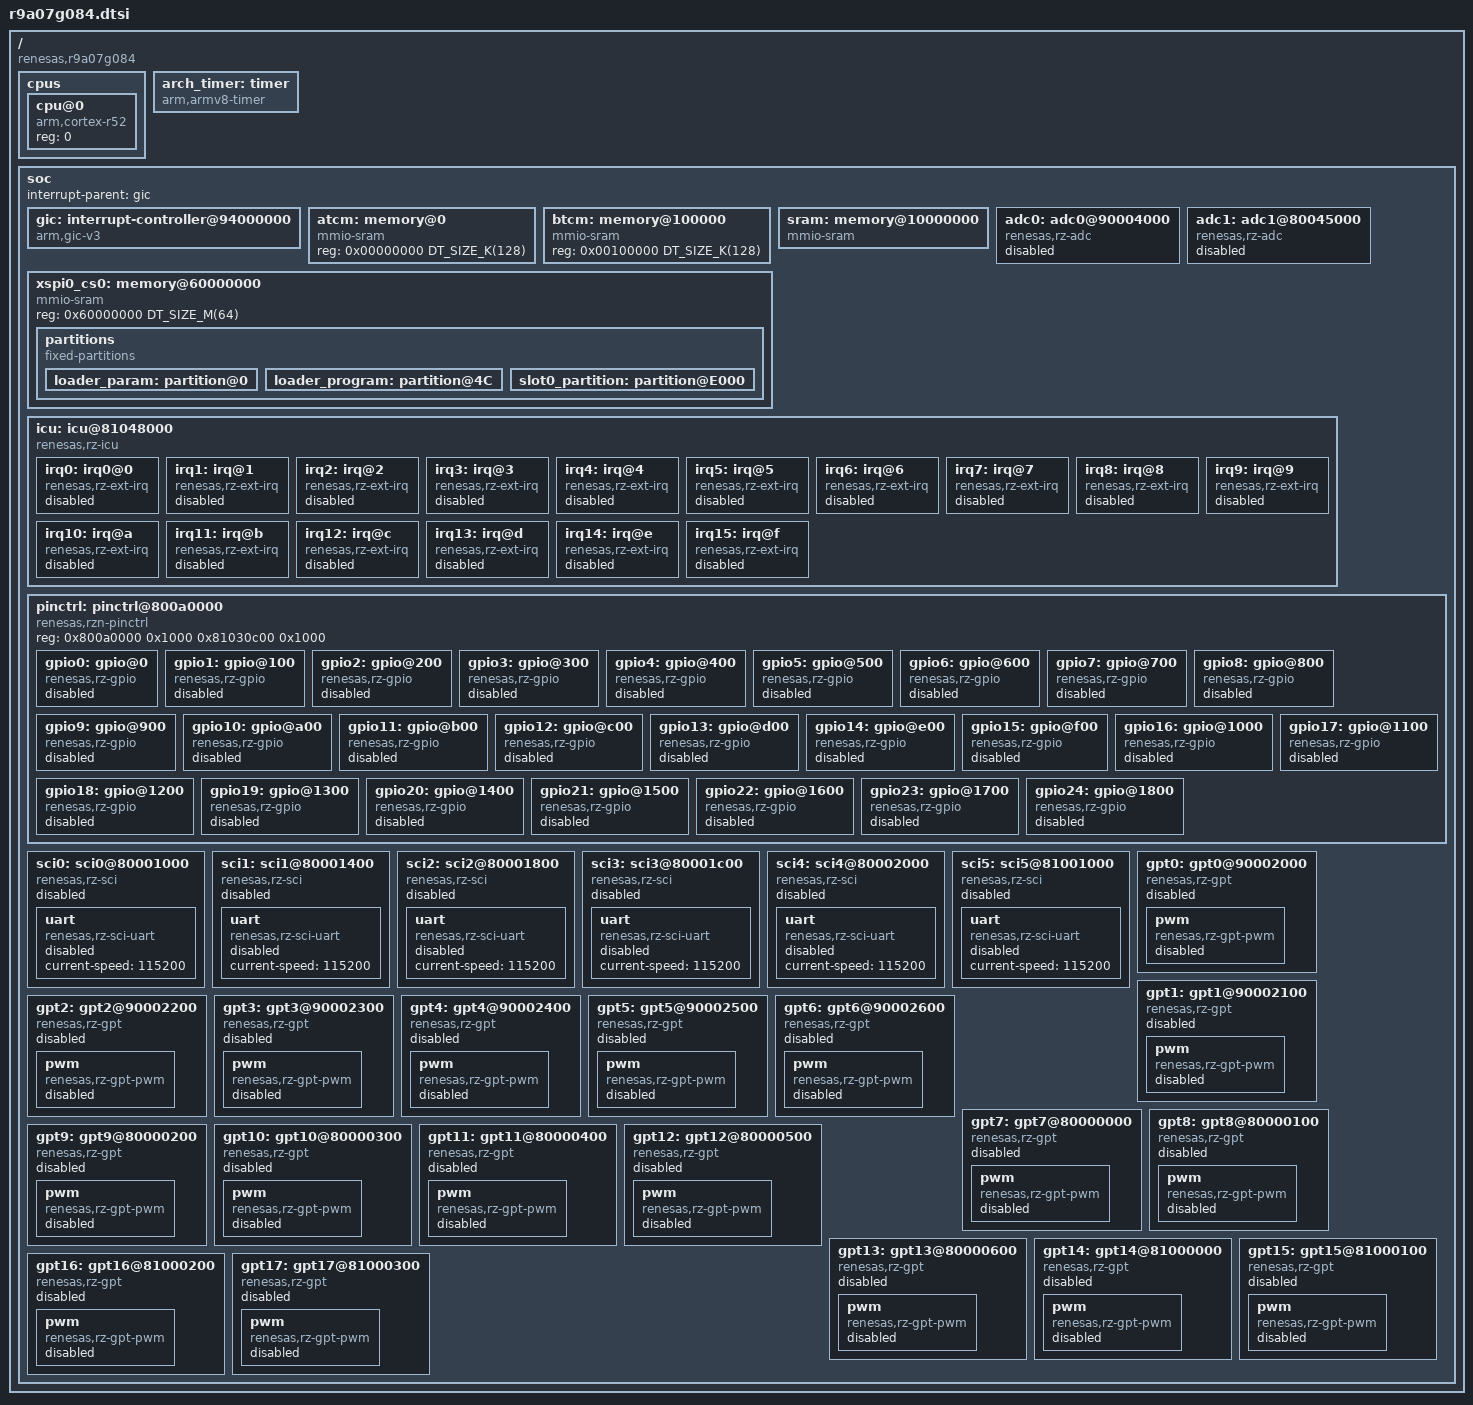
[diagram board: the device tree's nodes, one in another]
/*
 * Copyright (c) 2025 Renesas Electronics Corporation
 * SPDX-License-Identifier: Apache-2.0
 */

#include <mem.h>
#include <arm/armv8-r.dtsi>
#include <zephyr/dt-bindings/interrupt-controller/arm-gic.h>
#include <zephyr/dt-bindings/adc/adc.h>

/ {
	#address-cells = <1>;
	#size-cells = <1>;
	compatible = "renesas,r9a07g084";

	cpus {
		#address-cells = <1>;
		#size-cells = <0>;

		cpu@0 {
			device_type = "cpu";
			compatible = "arm,cortex-r52";
			reg = <0>;
		};
	};

	arch_timer: timer {
		compatible = "arm,armv8-timer";
		interrupts = <GIC_PPI 13 IRQ_TYPE_LEVEL IRQ_DEFAULT_PRIORITY>,
				<GIC_PPI 14 IRQ_TYPE_LEVEL IRQ_DEFAULT_PRIORITY>,
				<GIC_PPI 11 IRQ_TYPE_LEVEL IRQ_DEFAULT_PRIORITY>,
				<GIC_PPI 10 IRQ_TYPE_LEVEL IRQ_DEFAULT_PRIORITY>;
		interrupt-parent = <&gic>;
	};

	soc {
		interrupt-parent = <&gic>;

		gic: interrupt-controller@94000000 {
			compatible = "arm,gic-v3", "arm,gic";
			reg = <0x94000000 0x10000>,
				<0x94100000 0x80000>;
			interrupt-controller;
			#interrupt-cells = <4>;
			status = "okay";
		};

		atcm: memory@0 {
			compatible = "mmio-sram";
			reg = <0x00000000 DT_SIZE_K(128)>;
		};

		btcm: memory@100000 {
			compatible = "mmio-sram";
			reg = <0x00100000 DT_SIZE_K(128)>;
		};

		sram: memory@10000000 {
			compatible = "mmio-sram";
			reg = <0x10000000 (DT_SIZE_M(1) + DT_SIZE_K(512))>;
		};

		xspi0_cs0: memory@60000000 {
			compatible = "mmio-sram";
			reg = <0x60000000 DT_SIZE_M(64)>;

			partitions {
				compatible = "fixed-partitions";
				#address-cells = <1>;
				#size-cells = <1>;

				loader_param: partition@0 {
					label = "loader-param";
					reg = <0x00000000 0x4C>;
					read-only;
				};

				loader_program: partition@4C {
					label = "loader-program";
					reg = <0x0000004C (DT_SIZE_K(56) - 0x4C)>;
					read-only;
				};

				slot0_partition: partition@E000 {
					label = "image-0";
					reg = <0x0000E000 (DT_SIZE_M(64) - DT_SIZE_K(56))>;
					read-only;
				};
			};
		};

		adc0: adc0@90004000 {
			compatible = "renesas,rz-adc";
			reg = <0x90004000 0x1000>;
			unit = <0>;
			interrupts = <GIC_SPI 345 IRQ_TYPE_EDGE IRQ_DEFAULT_PRIORITY>;
			interrupt-names = "scanend";
			#io-channel-cells = <1>;
			vref-mv = <1800>;
			channel-available-mask = <0xF>;
			status = "disabled";
		};

		adc1: adc1@80045000 {
			compatible = "renesas,rz-adc";
			reg = <0x80045000 0x1000>;
			unit = <1>;
			interrupts = <GIC_SPI 350 IRQ_TYPE_EDGE IRQ_DEFAULT_PRIORITY>;
			interrupt-names = "scanend";
			#io-channel-cells = <1>;
			vref-mv = <1800>;
			channel-available-mask = <0xFF>;
			status = "disabled";
		};

		icu: icu@81048000 {
			compatible = "renesas,rz-icu";
			reg = <0x81048000 0x1000>;
			interrupt-parent = <&gic>;
			#address-cells = <1>;
			#size-cells = <0>;

			irq0: irq0@0 {
				compatible = "renesas,rz-ext-irq";
				reg = <0x0>;
				interrupts = <GIC_SPI 6 IRQ_TYPE_EDGE IRQ_DEFAULT_PRIORITY>;
				interrupt-controller;
				#interrupt-cells = <2>;
				status = "disabled";
			};

			irq1: irq@1 {
				compatible = "renesas,rz-ext-irq";
				reg = <0x1>;
				interrupts = <GIC_SPI 7 IRQ_TYPE_EDGE IRQ_DEFAULT_PRIORITY>;
				interrupt-controller;
				#interrupt-cells = <2>;
				status = "disabled";
			};

			irq2: irq@2 {
				compatible = "renesas,rz-ext-irq";
				reg = <0x2>;
				interrupts = <GIC_SPI 8 IRQ_TYPE_EDGE IRQ_DEFAULT_PRIORITY>;
				interrupt-controller;
				#interrupt-cells = <2>;
				status = "disabled";
			};

			irq3: irq@3 {
				compatible = "renesas,rz-ext-irq";
				reg = <0x3>;
				interrupts = <GIC_SPI 9 IRQ_TYPE_EDGE IRQ_DEFAULT_PRIORITY>;
				interrupt-controller;
				#interrupt-cells = <2>;
				status = "disabled";
			};

			irq4: irq@4 {
				compatible = "renesas,rz-ext-irq";
				reg = <0x4>;
				interrupts = <GIC_SPI 10 IRQ_TYPE_EDGE IRQ_DEFAULT_PRIORITY>;
				interrupt-controller;
				#interrupt-cells = <2>;
				status = "disabled";
			};

			irq5: irq@5 {
				compatible = "renesas,rz-ext-irq";
				reg = <0x5>;
				interrupts = <GIC_SPI 11 IRQ_TYPE_EDGE IRQ_DEFAULT_PRIORITY>;
				interrupt-controller;
				#interrupt-cells = <2>;
				status = "disabled";
			};

			irq6: irq@6 {
				compatible = "renesas,rz-ext-irq";
				reg = <0x6>;
				interrupts = <GIC_SPI 12 IRQ_TYPE_EDGE IRQ_DEFAULT_PRIORITY>;
				interrupt-controller;
				#interrupt-cells = <2>;
				status = "disabled";
			};

			irq7: irq@7 {
				compatible = "renesas,rz-ext-irq";
				reg = <0x7>;
				interrupts = <GIC_SPI 13 IRQ_TYPE_EDGE IRQ_DEFAULT_PRIORITY>;
				interrupt-controller;
				#interrupt-cells = <2>;
				status = "disabled";
			};

			irq8: irq@8 {
				compatible = "renesas,rz-ext-irq";
				reg = <0x8>;
				interrupts = <GIC_SPI 14 IRQ_TYPE_EDGE IRQ_DEFAULT_PRIORITY>;
				interrupt-controller;
				#interrupt-cells = <2>;
				status = "disabled";
			};

			irq9: irq@9 {
				compatible = "renesas,rz-ext-irq";
				reg = <0x9>;
				interrupts = <GIC_SPI 15 IRQ_TYPE_EDGE IRQ_DEFAULT_PRIORITY>;
				interrupt-controller;
				#interrupt-cells = <2>;
				status = "disabled";
			};

			irq10: irq@a {
				compatible = "renesas,rz-ext-irq";
				reg = <0xa>;
				interrupts = <GIC_SPI 16 IRQ_TYPE_EDGE IRQ_DEFAULT_PRIORITY>;
				interrupt-controller;
				#interrupt-cells = <2>;
				status = "disabled";
			};

			irq11: irq@b {
				compatible = "renesas,rz-ext-irq";
				reg = <0xb>;
				interrupts = <GIC_SPI 17 IRQ_TYPE_EDGE IRQ_DEFAULT_PRIORITY>;
				interrupt-controller;
				#interrupt-cells = <2>;
				status = "disabled";
			};

			irq12: irq@c {
				compatible = "renesas,rz-ext-irq";
				reg = <0xc>;
				interrupts = <GIC_SPI 18 IRQ_TYPE_EDGE IRQ_DEFAULT_PRIORITY>;
				interrupt-controller;
				#interrupt-cells = <2>;
				status = "disabled";
			};

			irq13: irq@d {
				compatible = "renesas,rz-ext-irq";
				reg = <0xd>;
				interrupts = <GIC_SPI 19 IRQ_TYPE_EDGE IRQ_DEFAULT_PRIORITY>;
				interrupt-controller;
				#interrupt-cells = <2>;
				status = "disabled";
			};

			irq14: irq@e {
				compatible = "renesas,rz-ext-irq";
				reg = <0xe>;
				interrupts = <GIC_SPI 394 IRQ_TYPE_EDGE IRQ_DEFAULT_PRIORITY>;
				interrupt-controller;
				#interrupt-cells = <2>;
				status = "disabled";
			};

			irq15: irq@f {
				compatible = "renesas,rz-ext-irq";
				reg = <0xf>;
				interrupts = <GIC_SPI 395 IRQ_TYPE_EDGE IRQ_DEFAULT_PRIORITY>;
				interrupt-controller;
				#interrupt-cells = <2>;
				status = "disabled";
			};
		};

		pinctrl: pinctrl@800a0000 {
			compatible = "renesas,rzn-pinctrl";
			reg = <0x800a0000 0x1000 0x81030c00 0x1000>;
			#address-cells = <1>;
			#size-cells = <0>;

			gpio0: gpio@0 {
				compatible = "renesas,rz-gpio";
				gpio-controller;
				#gpio-cells = <2>;
				ngpios = <8>;
				reg = <0x0>;
				status = "disabled";
			};

			gpio1: gpio@100 {
				compatible = "renesas,rz-gpio";
				gpio-controller;
				#gpio-cells= <2>;
				ngpios = <8>;
				reg = <0x0100>;
				status = "disabled";
			};

			gpio2: gpio@200 {
				compatible = "renesas,rz-gpio";
				gpio-controller;
				#gpio-cells= <2>;
				ngpios = <8>;
				reg = <0x0200>;
				status = "disabled";
			};

			gpio3: gpio@300 {
				compatible = "renesas,rz-gpio";
				gpio-controller;
				#gpio-cells= <2>;
				ngpios = <8>;
				gpio-reserved-ranges = <1 4>;
				reg = <0x0300>;
				status = "disabled";
			};

			gpio4: gpio@400 {
				compatible = "renesas,rz-gpio";
				gpio-controller;
				#gpio-cells= <2>;
				ngpios = <8>;
				gpio-reserved-ranges = <2 2>;
				reg = <0x0400>;
				status = "disabled";
			};

			gpio5: gpio@500 {
				compatible = "renesas,rz-gpio";
				gpio-controller;
				#gpio-cells= <2>;
				ngpios = <8>;
				reg = <0x0500>;
				status = "disabled";
			};

			gpio6: gpio@600 {
				compatible = "renesas,rz-gpio";
				gpio-controller;
				#gpio-cells= <2>;
				ngpios = <8>;
				reg = <0x0600>;
				status = "disabled";
			};

			gpio7: gpio@700 {
				compatible = "renesas,rz-gpio";
				gpio-controller;
				#gpio-cells= <2>;
				ngpios = <5>;
				reg = <0x0700>;
				status = "disabled";
			};

			gpio8: gpio@800 {
				compatible = "renesas,rz-gpio";
				gpio-controller;
				#gpio-cells= <2>;
				ngpios = <8>;
				gpio-reserved-ranges = <0 4>;
				reg = <0x0800>;
				status = "disabled";
			};

			gpio9: gpio@900 {
				compatible = "renesas,rz-gpio";
				gpio-controller;
				#gpio-cells= <2>;
				ngpios = <8>;
				reg = <0x0900>;
				status = "disabled";
			};

			gpio10: gpio@a00 {
				compatible = "renesas,rz-gpio";
				gpio-controller;
				#gpio-cells= <2>;
				ngpios = <5>;
				reg = <0x0a00>;
				status = "disabled";
			};

			gpio11: gpio@b00 {
				compatible = "renesas,rz-gpio";
				gpio-controller;
				#gpio-cells= <2>;
				ngpios = <0>;
				reg = <0x0b00>;
				status = "disabled";
			};

			gpio12: gpio@c00 {
				compatible = "renesas,rz-gpio";
				gpio-controller;
				#gpio-cells= <2>;
				ngpios = <5>;
				gpio-reserved-ranges = <0 4>;
				reg = <0x0c00>;
				status = "disabled";
			};

			gpio13: gpio@d00 {
				compatible = "renesas,rz-gpio";
				gpio-controller;
				#gpio-cells= <2>;
				ngpios = <8>;
				gpio-reserved-ranges = <0 2>;
				reg = <0x0d00>;
				status = "disabled";
			};

			gpio14: gpio@e00 {
				compatible = "renesas,rz-gpio";
				gpio-controller;
				#gpio-cells= <2>;
				ngpios = <8>;
				reg = <0x0e00>;
				status = "disabled";
			};

			gpio15: gpio@f00 {
				compatible = "renesas,rz-gpio";
				gpio-controller;
				#gpio-cells= <2>;
				ngpios = <8>;
				reg = <0x0f00>;
				status = "disabled";
			};

			gpio16: gpio@1000 {
				compatible = "renesas,rz-gpio";
				gpio-controller;
				#gpio-cells= <2>;
				ngpios = <8>;
				gpio-reserved-ranges = <4 1>;
				reg = <0x1000>;
				status = "disabled";
			};

			gpio17: gpio@1100 {
				compatible = "renesas,rz-gpio";
				gpio-controller;
				#gpio-cells= <2>;
				ngpios = <8>;
				gpio-reserved-ranges = <1 2>;
				reg = <0x1100>;
				status = "disabled";
			};

			gpio18: gpio@1200 {
				compatible = "renesas,rz-gpio";
				gpio-controller;
				#gpio-cells= <2>;
				ngpios = <7>;
				reg = <0x1200>;
				status = "disabled";
			};

			gpio19: gpio@1300 {
				compatible = "renesas,rz-gpio";
				gpio-controller;
				#gpio-cells= <2>;
				ngpios = <1>;
				reg = <0x1300>;
				status = "disabled";
			};

			gpio20: gpio@1400 {
				compatible = "renesas,rz-gpio";
				gpio-controller;
				#gpio-cells= <2>;
				ngpios = <5>;
				gpio-reserved-ranges = <0 1>;
				reg = <0x1400>;
				status = "disabled";
			};

			gpio21: gpio@1500 {
				compatible = "renesas,rz-gpio";
				gpio-controller;
				#gpio-cells= <2>;
				ngpios = <8>;
				gpio-reserved-ranges = <0 1>;
				reg = <0x1500>;
				status = "disabled";
			};

			gpio22: gpio@1600 {
				compatible = "renesas,rz-gpio";
				gpio-controller;
				#gpio-cells= <2>;
				ngpios = <4>;
				reg = <0x1600>;
				status = "disabled";
			};

			gpio23: gpio@1700 {
				compatible = "renesas,rz-gpio";
				gpio-controller;
				#gpio-cells= <2>;
				ngpios = <8>;
				gpio-reserved-ranges = <0 7>;
				reg = <0x1700>;
				status = "disabled";
			};

			gpio24: gpio@1800 {
				compatible = "renesas,rz-gpio";
				gpio-controller;
				#gpio-cells= <2>;
				ngpios = <3>;
				reg = <0x1800>;
				status = "disabled";
			};
		};

		sci0: sci0@80001000 {
			compatible = "renesas,rz-sci";
			reg = <0x80001000 0x400>;
			channel = <0>;
			interrupts = <GIC_SPI 288 IRQ_TYPE_LEVEL IRQ_DEFAULT_PRIORITY>,
					<GIC_SPI 289 IRQ_TYPE_EDGE IRQ_DEFAULT_PRIORITY>,
					<GIC_SPI 290 IRQ_TYPE_EDGE IRQ_DEFAULT_PRIORITY>,
					<GIC_SPI 291 IRQ_TYPE_LEVEL IRQ_DEFAULT_PRIORITY>;
			interrupt-names = "eri", "rxi", "txi", "tei";
			status = "disabled";

			uart {
				compatible = "renesas,rz-sci-uart";
				current-speed = <115200>;
				status = "disabled";
			};
		};

		sci1: sci1@80001400 {
			compatible = "renesas,rz-sci";
			reg = <0x80001400 0x400>;
			channel = <1>;
			interrupts = <GIC_SPI 292 IRQ_TYPE_LEVEL IRQ_DEFAULT_PRIORITY>,
					<GIC_SPI 293 IRQ_TYPE_EDGE IRQ_DEFAULT_PRIORITY>,
					<GIC_SPI 294 IRQ_TYPE_EDGE IRQ_DEFAULT_PRIORITY>,
					<GIC_SPI 295 IRQ_TYPE_LEVEL IRQ_DEFAULT_PRIORITY>;
			interrupt-names = "eri", "rxi", "txi", "tei";
			status = "disabled";

			uart {
				compatible = "renesas,rz-sci-uart";
				current-speed = <115200>;
				status = "disabled";
			};
		};

		sci2: sci2@80001800 {
			compatible = "renesas,rz-sci";
			reg = <0x80001800 0x400>;
			channel = <2>;
			interrupts = <GIC_SPI 296 IRQ_TYPE_LEVEL IRQ_DEFAULT_PRIORITY>,
					<GIC_SPI 297 IRQ_TYPE_EDGE IRQ_DEFAULT_PRIORITY>,
					<GIC_SPI 298 IRQ_TYPE_EDGE IRQ_DEFAULT_PRIORITY>,
					<GIC_SPI 299 IRQ_TYPE_LEVEL IRQ_DEFAULT_PRIORITY>;
			interrupt-names = "eri", "rxi", "txi", "tei";
			status = "disabled";

			uart {
				compatible = "renesas,rz-sci-uart";
				current-speed = <115200>;
				status = "disabled";
			};
		};

		sci3: sci3@80001c00 {
			compatible = "renesas,rz-sci";
			reg = <0x80001c00 0x400>;
			channel = <3>;
			interrupts = <GIC_SPI 300 IRQ_TYPE_LEVEL IRQ_DEFAULT_PRIORITY>,
					<GIC_SPI 301 IRQ_TYPE_EDGE IRQ_DEFAULT_PRIORITY>,
					<GIC_SPI 302 IRQ_TYPE_EDGE IRQ_DEFAULT_PRIORITY>,
					<GIC_SPI 303 IRQ_TYPE_LEVEL IRQ_DEFAULT_PRIORITY>;
			interrupt-names = "eri", "rxi", "txi", "tei";
			status = "disabled";

			uart {
				compatible = "renesas,rz-sci-uart";
				current-speed = <115200>;
				status = "disabled";
			};
		};

		sci4: sci4@80002000 {
			compatible = "renesas,rz-sci";
			reg = <0x80002000 0x400>;
			channel = <4>;
			interrupts = <GIC_SPI 304 IRQ_TYPE_LEVEL IRQ_DEFAULT_PRIORITY>,
					<GIC_SPI 305 IRQ_TYPE_EDGE IRQ_DEFAULT_PRIORITY>,
					<GIC_SPI 306 IRQ_TYPE_EDGE IRQ_DEFAULT_PRIORITY>,
					<GIC_SPI 307 IRQ_TYPE_LEVEL IRQ_DEFAULT_PRIORITY>;
			interrupt-names = "eri", "rxi", "txi", "tei";
			status = "disabled";

			uart {
				compatible = "renesas,rz-sci-uart";
				current-speed = <115200>;
				status = "disabled";
			};
		};

		sci5: sci5@81001000 {
			compatible = "renesas,rz-sci";
			reg = <0x81001000 0x400>;
			channel = <5>;
			interrupts = <GIC_SPI 435 IRQ_TYPE_LEVEL IRQ_DEFAULT_PRIORITY>,
					<GIC_SPI 436 IRQ_TYPE_EDGE IRQ_DEFAULT_PRIORITY>,
					<GIC_SPI 437 IRQ_TYPE_EDGE IRQ_DEFAULT_PRIORITY>,
					<GIC_SPI 438 IRQ_TYPE_LEVEL IRQ_DEFAULT_PRIORITY>;
			interrupt-names = "eri", "rxi", "txi", "tei";
			status = "disabled";

			uart {
				compatible = "renesas,rz-sci-uart";
				current-speed = <115200>;
				status = "disabled";
			};
		};

		gpt0: gpt0@90002000 {
			compatible = "renesas,rz-gpt";
			reg = <0x90002000 0x100>;
			channel = <0>;
			interrupts = <GIC_SPI 116 IRQ_TYPE_EDGE IRQ_DEFAULT_PRIORITY>,
					<GIC_SPI 117 IRQ_TYPE_EDGE IRQ_DEFAULT_PRIORITY>,
					<GIC_SPI 118 IRQ_TYPE_EDGE IRQ_DEFAULT_PRIORITY>,
					<GIC_SPI 119 IRQ_TYPE_EDGE IRQ_DEFAULT_PRIORITY>,
					<GIC_SPI 120 IRQ_TYPE_EDGE IRQ_DEFAULT_PRIORITY>,
					<GIC_SPI 121 IRQ_TYPE_EDGE IRQ_DEFAULT_PRIORITY>,
					<GIC_SPI 122 IRQ_TYPE_EDGE IRQ_DEFAULT_PRIORITY>,
					<GIC_SPI 123 IRQ_TYPE_EDGE IRQ_DEFAULT_PRIORITY>,
					<GIC_SPI 124 IRQ_TYPE_EDGE IRQ_DEFAULT_PRIORITY>;
			interrupt-names = "ccmpa", "ccmpb", "cmpc", "cmpd", "cmpe",
					  "cmpf", "ovf", "udf", "dte";
			prescaler = <1>;
			status = "disabled";

			pwm {
				compatible = "renesas,rz-gpt-pwm";
				#pwm-cells = <3>;
				status = "disabled";
			};
		};

		gpt1: gpt1@90002100 {
			compatible = "renesas,rz-gpt";
			reg = <0x90002100 0x100>;
			channel = <1>;
			interrupts = <GIC_SPI 125 IRQ_TYPE_EDGE IRQ_DEFAULT_PRIORITY>,
					<GIC_SPI 126 IRQ_TYPE_EDGE IRQ_DEFAULT_PRIORITY>,
					<GIC_SPI 127 IRQ_TYPE_EDGE IRQ_DEFAULT_PRIORITY>,
					<GIC_SPI 128 IRQ_TYPE_EDGE IRQ_DEFAULT_PRIORITY>,
					<GIC_SPI 129 IRQ_TYPE_EDGE IRQ_DEFAULT_PRIORITY>,
					<GIC_SPI 130 IRQ_TYPE_EDGE IRQ_DEFAULT_PRIORITY>,
					<GIC_SPI 131 IRQ_TYPE_EDGE IRQ_DEFAULT_PRIORITY>,
					<GIC_SPI 132 IRQ_TYPE_EDGE IRQ_DEFAULT_PRIORITY>,
					<GIC_SPI 133 IRQ_TYPE_EDGE IRQ_DEFAULT_PRIORITY>;
			interrupt-names = "ccmpa", "ccmpb", "cmpc", "cmpd", "cmpe",
					  "cmpf", "ovf", "udf", "dte";
			prescaler = <1>;
			status = "disabled";

			pwm {
				compatible = "renesas,rz-gpt-pwm";
				#pwm-cells = <3>;
				status = "disabled";
			};
		};

		gpt2: gpt2@90002200 {
			compatible = "renesas,rz-gpt";
			reg = <0x90002200 0x100>;
			channel = <2>;
			interrupts = <GIC_SPI 134 IRQ_TYPE_EDGE IRQ_DEFAULT_PRIORITY>,
					<GIC_SPI 135 IRQ_TYPE_EDGE IRQ_DEFAULT_PRIORITY>,
					<GIC_SPI 136 IRQ_TYPE_EDGE IRQ_DEFAULT_PRIORITY>,
					<GIC_SPI 137 IRQ_TYPE_EDGE IRQ_DEFAULT_PRIORITY>,
					<GIC_SPI 138 IRQ_TYPE_EDGE IRQ_DEFAULT_PRIORITY>,
					<GIC_SPI 139 IRQ_TYPE_EDGE IRQ_DEFAULT_PRIORITY>,
					<GIC_SPI 140 IRQ_TYPE_EDGE IRQ_DEFAULT_PRIORITY>,
					<GIC_SPI 141 IRQ_TYPE_EDGE IRQ_DEFAULT_PRIORITY>,
					<GIC_SPI 142 IRQ_TYPE_EDGE IRQ_DEFAULT_PRIORITY>;
			interrupt-names = "ccmpa", "ccmpb", "cmpc", "cmpd", "cmpe",
					  "cmpf", "ovf", "udf", "dte";
			prescaler = <1>;
			status = "disabled";

			pwm {
				compatible = "renesas,rz-gpt-pwm";
				#pwm-cells = <3>;
				status = "disabled";
			};
		};

		gpt3: gpt3@90002300 {
			compatible = "renesas,rz-gpt";
			reg = <0x90002300 0x100>;
			channel = <3>;
			interrupts = <GIC_SPI 143 IRQ_TYPE_EDGE IRQ_DEFAULT_PRIORITY>,
					<GIC_SPI 144 IRQ_TYPE_EDGE IRQ_DEFAULT_PRIORITY>,
					<GIC_SPI 145 IRQ_TYPE_EDGE IRQ_DEFAULT_PRIORITY>,
					<GIC_SPI 146 IRQ_TYPE_EDGE IRQ_DEFAULT_PRIORITY>,
					<GIC_SPI 147 IRQ_TYPE_EDGE IRQ_DEFAULT_PRIORITY>,
					<GIC_SPI 148 IRQ_TYPE_EDGE IRQ_DEFAULT_PRIORITY>,
					<GIC_SPI 149 IRQ_TYPE_EDGE IRQ_DEFAULT_PRIORITY>,
					<GIC_SPI 150 IRQ_TYPE_EDGE IRQ_DEFAULT_PRIORITY>,
					<GIC_SPI 151 IRQ_TYPE_EDGE IRQ_DEFAULT_PRIORITY>;
			interrupt-names = "ccmpa", "ccmpb", "cmpc", "cmpd", "cmpe",
					  "cmpf", "ovf", "udf", "dte";
			prescaler = <1>;
			status = "disabled";

			pwm {
				compatible = "renesas,rz-gpt-pwm";
				#pwm-cells = <3>;
				status = "disabled";
			};
		};

		gpt4: gpt4@90002400 {
			compatible = "renesas,rz-gpt";
			reg = <0x90002400 0x100>;
			channel = <4>;
			interrupts = <GIC_SPI 152 IRQ_TYPE_EDGE IRQ_DEFAULT_PRIORITY>,
					<GIC_SPI 153 IRQ_TYPE_EDGE IRQ_DEFAULT_PRIORITY>,
					<GIC_SPI 154 IRQ_TYPE_EDGE IRQ_DEFAULT_PRIORITY>,
					<GIC_SPI 155 IRQ_TYPE_EDGE IRQ_DEFAULT_PRIORITY>,
					<GIC_SPI 156 IRQ_TYPE_EDGE IRQ_DEFAULT_PRIORITY>,
					<GIC_SPI 157 IRQ_TYPE_EDGE IRQ_DEFAULT_PRIORITY>,
					<GIC_SPI 158 IRQ_TYPE_EDGE IRQ_DEFAULT_PRIORITY>,
					<GIC_SPI 159 IRQ_TYPE_EDGE IRQ_DEFAULT_PRIORITY>,
					<GIC_SPI 160 IRQ_TYPE_EDGE IRQ_DEFAULT_PRIORITY>;
			interrupt-names = "ccmpa", "ccmpb", "cmpc", "cmpd", "cmpe",
					  "cmpf", "ovf", "udf", "dte";
			prescaler = <1>;
			status = "disabled";

			pwm {
				compatible = "renesas,rz-gpt-pwm";
				#pwm-cells = <3>;
				status = "disabled";
			};
		};

		gpt5: gpt5@90002500 {
			compatible = "renesas,rz-gpt";
			reg = <0x90002500 0x100>;
			channel = <5>;
			interrupts = <GIC_SPI 161 IRQ_TYPE_EDGE IRQ_DEFAULT_PRIORITY>,
					<GIC_SPI 162 IRQ_TYPE_EDGE IRQ_DEFAULT_PRIORITY>,
					<GIC_SPI 163 IRQ_TYPE_EDGE IRQ_DEFAULT_PRIORITY>,
					<GIC_SPI 164 IRQ_TYPE_EDGE IRQ_DEFAULT_PRIORITY>,
					<GIC_SPI 165 IRQ_TYPE_EDGE IRQ_DEFAULT_PRIORITY>,
					<GIC_SPI 166 IRQ_TYPE_EDGE IRQ_DEFAULT_PRIORITY>,
					<GIC_SPI 167 IRQ_TYPE_EDGE IRQ_DEFAULT_PRIORITY>,
					<GIC_SPI 168 IRQ_TYPE_EDGE IRQ_DEFAULT_PRIORITY>,
					<GIC_SPI 169 IRQ_TYPE_EDGE IRQ_DEFAULT_PRIORITY>;
			interrupt-names = "ccmpa", "ccmpb", "cmpc", "cmpd", "cmpe",
					  "cmpf", "ovf", "udf", "dte";
			prescaler = <1>;
			status = "disabled";

			pwm {
				compatible = "renesas,rz-gpt-pwm";
				#pwm-cells = <3>;
				status = "disabled";
			};
		};

		gpt6: gpt6@90002600 {
			compatible = "renesas,rz-gpt";
			reg = <0x90002600 0x100>;
			channel = <6>;
			interrupts = <GIC_SPI 170 IRQ_TYPE_EDGE IRQ_DEFAULT_PRIORITY>,
					<GIC_SPI 171 IRQ_TYPE_EDGE IRQ_DEFAULT_PRIORITY>,
					<GIC_SPI 172 IRQ_TYPE_EDGE IRQ_DEFAULT_PRIORITY>,
					<GIC_SPI 173 IRQ_TYPE_EDGE IRQ_DEFAULT_PRIORITY>,
					<GIC_SPI 174 IRQ_TYPE_EDGE IRQ_DEFAULT_PRIORITY>,
					<GIC_SPI 175 IRQ_TYPE_EDGE IRQ_DEFAULT_PRIORITY>,
					<GIC_SPI 176 IRQ_TYPE_EDGE IRQ_DEFAULT_PRIORITY>,
					<GIC_SPI 177 IRQ_TYPE_EDGE IRQ_DEFAULT_PRIORITY>,
					<GIC_SPI 178 IRQ_TYPE_EDGE IRQ_DEFAULT_PRIORITY>;
			interrupt-names = "ccmpa", "ccmpb", "cmpc", "cmpd", "cmpe",
					  "cmpf", "ovf", "udf", "dte";
			prescaler = <1>;
			status = "disabled";

			pwm {
				compatible = "renesas,rz-gpt-pwm";
				#pwm-cells = <3>;
				status = "disabled";
			};
		};

		gpt7: gpt7@80000000 {
			compatible = "renesas,rz-gpt";
			reg = <0x80000000 0x100>;
			channel = <7>;
			interrupts = <GIC_SPI 179 IRQ_TYPE_EDGE IRQ_DEFAULT_PRIORITY>,
					<GIC_SPI 180 IRQ_TYPE_EDGE IRQ_DEFAULT_PRIORITY>,
					<GIC_SPI 181 IRQ_TYPE_EDGE IRQ_DEFAULT_PRIORITY>,
					<GIC_SPI 182 IRQ_TYPE_EDGE IRQ_DEFAULT_PRIORITY>,
					<GIC_SPI 183 IRQ_TYPE_EDGE IRQ_DEFAULT_PRIORITY>,
					<GIC_SPI 184 IRQ_TYPE_EDGE IRQ_DEFAULT_PRIORITY>,
					<GIC_SPI 185 IRQ_TYPE_EDGE IRQ_DEFAULT_PRIORITY>,
					<GIC_SPI 186 IRQ_TYPE_EDGE IRQ_DEFAULT_PRIORITY>,
					<GIC_SPI 187 IRQ_TYPE_EDGE IRQ_DEFAULT_PRIORITY>;
			interrupt-names = "ccmpa", "ccmpb", "cmpc", "cmpd", "cmpe",
					  "cmpf", "ovf", "udf", "dte";
			prescaler = <1>;
			status = "disabled";

			pwm {
				compatible = "renesas,rz-gpt-pwm";
				#pwm-cells = <3>;
				status = "disabled";
			};
		};

		gpt8: gpt8@80000100 {
			compatible = "renesas,rz-gpt";
			reg = <0x80000100 0x100>;
			channel = <8>;
			interrupts = <GIC_SPI 188 IRQ_TYPE_EDGE IRQ_DEFAULT_PRIORITY>,
					<GIC_SPI 189 IRQ_TYPE_EDGE IRQ_DEFAULT_PRIORITY>,
					<GIC_SPI 190 IRQ_TYPE_EDGE IRQ_DEFAULT_PRIORITY>,
					<GIC_SPI 191 IRQ_TYPE_EDGE IRQ_DEFAULT_PRIORITY>,
					<GIC_SPI 192 IRQ_TYPE_EDGE IRQ_DEFAULT_PRIORITY>,
					<GIC_SPI 193 IRQ_TYPE_EDGE IRQ_DEFAULT_PRIORITY>,
					<GIC_SPI 194 IRQ_TYPE_EDGE IRQ_DEFAULT_PRIORITY>,
					<GIC_SPI 195 IRQ_TYPE_EDGE IRQ_DEFAULT_PRIORITY>,
					<GIC_SPI 196 IRQ_TYPE_EDGE IRQ_DEFAULT_PRIORITY>;
			interrupt-names = "ccmpa", "ccmpb", "cmpc", "cmpd", "cmpe",
					  "cmpf", "ovf", "udf", "dte";
			prescaler = <1>;
			status = "disabled";

			pwm {
				compatible = "renesas,rz-gpt-pwm";
				#pwm-cells = <3>;
				status = "disabled";
			};
		};

		gpt9: gpt9@80000200 {
			compatible = "renesas,rz-gpt";
			reg = <0x80000200 0x100>;
			channel = <9>;
			interrupts = <GIC_SPI 197 IRQ_TYPE_EDGE IRQ_DEFAULT_PRIORITY>,
					<GIC_SPI 198 IRQ_TYPE_EDGE IRQ_DEFAULT_PRIORITY>,
					<GIC_SPI 199 IRQ_TYPE_EDGE IRQ_DEFAULT_PRIORITY>,
					<GIC_SPI 200 IRQ_TYPE_EDGE IRQ_DEFAULT_PRIORITY>,
					<GIC_SPI 201 IRQ_TYPE_EDGE IRQ_DEFAULT_PRIORITY>,
					<GIC_SPI 202 IRQ_TYPE_EDGE IRQ_DEFAULT_PRIORITY>,
					<GIC_SPI 203 IRQ_TYPE_EDGE IRQ_DEFAULT_PRIORITY>,
					<GIC_SPI 204 IRQ_TYPE_EDGE IRQ_DEFAULT_PRIORITY>,
					<GIC_SPI 205 IRQ_TYPE_EDGE IRQ_DEFAULT_PRIORITY>;
			interrupt-names = "ccmpa", "ccmpb", "cmpc", "cmpd", "cmpe",
					  "cmpf", "ovf", "udf", "dte";
			prescaler = <1>;
			status = "disabled";

			pwm {
				compatible = "renesas,rz-gpt-pwm";
				#pwm-cells = <3>;
				status = "disabled";
			};
		};

		gpt10: gpt10@80000300 {
			compatible = "renesas,rz-gpt";
			reg = <0x80000300 0x100>;
			channel = <10>;
			interrupts = <GIC_SPI 206 IRQ_TYPE_EDGE IRQ_DEFAULT_PRIORITY>,
					<GIC_SPI 207 IRQ_TYPE_EDGE IRQ_DEFAULT_PRIORITY>,
					<GIC_SPI 208 IRQ_TYPE_EDGE IRQ_DEFAULT_PRIORITY>,
					<GIC_SPI 209 IRQ_TYPE_EDGE IRQ_DEFAULT_PRIORITY>,
					<GIC_SPI 210 IRQ_TYPE_EDGE IRQ_DEFAULT_PRIORITY>,
					<GIC_SPI 211 IRQ_TYPE_EDGE IRQ_DEFAULT_PRIORITY>,
					<GIC_SPI 212 IRQ_TYPE_EDGE IRQ_DEFAULT_PRIORITY>,
					<GIC_SPI 213 IRQ_TYPE_EDGE IRQ_DEFAULT_PRIORITY>,
					<GIC_SPI 214 IRQ_TYPE_EDGE IRQ_DEFAULT_PRIORITY>;
			interrupt-names = "ccmpa", "ccmpb", "cmpc", "cmpd", "cmpe",
					  "cmpf", "ovf", "udf", "dte";
			prescaler = <1>;
			status = "disabled";

			pwm {
				compatible = "renesas,rz-gpt-pwm";
				#pwm-cells = <3>;
				status = "disabled";
			};
		};

		gpt11: gpt11@80000400 {
			compatible = "renesas,rz-gpt";
			reg = <0x80000400 0x100>;
			channel = <11>;
			interrupts = <GIC_SPI 215 IRQ_TYPE_EDGE IRQ_DEFAULT_PRIORITY>,
					<GIC_SPI 216 IRQ_TYPE_EDGE IRQ_DEFAULT_PRIORITY>,
					<GIC_SPI 217 IRQ_TYPE_EDGE IRQ_DEFAULT_PRIORITY>,
					<GIC_SPI 218 IRQ_TYPE_EDGE IRQ_DEFAULT_PRIORITY>,
					<GIC_SPI 219 IRQ_TYPE_EDGE IRQ_DEFAULT_PRIORITY>,
					<GIC_SPI 220 IRQ_TYPE_EDGE IRQ_DEFAULT_PRIORITY>,
					<GIC_SPI 221 IRQ_TYPE_EDGE IRQ_DEFAULT_PRIORITY>,
					<GIC_SPI 222 IRQ_TYPE_EDGE IRQ_DEFAULT_PRIORITY>,
					<GIC_SPI 223 IRQ_TYPE_EDGE IRQ_DEFAULT_PRIORITY>;
			interrupt-names = "ccmpa", "ccmpb", "cmpc", "cmpd", "cmpe",
					  "cmpf", "ovf", "udf", "dte";
			prescaler = <1>;
			status = "disabled";

			pwm {
				compatible = "renesas,rz-gpt-pwm";
				#pwm-cells = <3>;
				status = "disabled";
			};
		};

		gpt12: gpt12@80000500 {
			compatible = "renesas,rz-gpt";
			reg = <0x80000500 0x100>;
			channel = <12>;
			interrupts = <GIC_SPI 224 IRQ_TYPE_EDGE IRQ_DEFAULT_PRIORITY>,
					<GIC_SPI 225 IRQ_TYPE_EDGE IRQ_DEFAULT_PRIORITY>,
					<GIC_SPI 226 IRQ_TYPE_EDGE IRQ_DEFAULT_PRIORITY>,
					<GIC_SPI 227 IRQ_TYPE_EDGE IRQ_DEFAULT_PRIORITY>,
					<GIC_SPI 228 IRQ_TYPE_EDGE IRQ_DEFAULT_PRIORITY>,
					<GIC_SPI 229 IRQ_TYPE_EDGE IRQ_DEFAULT_PRIORITY>,
					<GIC_SPI 230 IRQ_TYPE_EDGE IRQ_DEFAULT_PRIORITY>,
					<GIC_SPI 231 IRQ_TYPE_EDGE IRQ_DEFAULT_PRIORITY>,
					<GIC_SPI 232 IRQ_TYPE_EDGE IRQ_DEFAULT_PRIORITY>;
			interrupt-names = "ccmpa", "ccmpb", "cmpc", "cmpd", "cmpe",
					  "cmpf", "ovf", "udf", "dte";
			prescaler = <1>;
			status = "disabled";

			pwm {
				compatible = "renesas,rz-gpt-pwm";
				#pwm-cells = <3>;
				status = "disabled";
			};
		};

		gpt13: gpt13@80000600 {
			compatible = "renesas,rz-gpt";
			reg = <0x80000600 0x100>;
			channel = <13>;
			interrupts = <GIC_SPI 233 IRQ_TYPE_EDGE IRQ_DEFAULT_PRIORITY>,
					<GIC_SPI 234 IRQ_TYPE_EDGE IRQ_DEFAULT_PRIORITY>,
					<GIC_SPI 235 IRQ_TYPE_EDGE IRQ_DEFAULT_PRIORITY>,
					<GIC_SPI 236 IRQ_TYPE_EDGE IRQ_DEFAULT_PRIORITY>,
					<GIC_SPI 237 IRQ_TYPE_EDGE IRQ_DEFAULT_PRIORITY>,
					<GIC_SPI 238 IRQ_TYPE_EDGE IRQ_DEFAULT_PRIORITY>,
					<GIC_SPI 239 IRQ_TYPE_EDGE IRQ_DEFAULT_PRIORITY>,
					<GIC_SPI 240 IRQ_TYPE_EDGE IRQ_DEFAULT_PRIORITY>,
					<GIC_SPI 241 IRQ_TYPE_EDGE IRQ_DEFAULT_PRIORITY>;
			interrupt-names = "ccmpa", "ccmpb", "cmpc", "cmpd", "cmpe",
					  "cmpf", "ovf", "udf", "dte";
			prescaler = <1>;
			status = "disabled";

			pwm {
				compatible = "renesas,rz-gpt-pwm";
				#pwm-cells = <3>;
				status = "disabled";
			};
		};

		gpt14: gpt14@81000000 {
			compatible = "renesas,rz-gpt";
			reg = <0x81000000 0x100>;
			channel = <14>;
			interrupts = <GIC_SPI 396 IRQ_TYPE_EDGE IRQ_DEFAULT_PRIORITY>,
					<GIC_SPI 397 IRQ_TYPE_EDGE IRQ_DEFAULT_PRIORITY>,
					<GIC_SPI 398 IRQ_TYPE_EDGE IRQ_DEFAULT_PRIORITY>,
					<GIC_SPI 399 IRQ_TYPE_EDGE IRQ_DEFAULT_PRIORITY>,
					<GIC_SPI 400 IRQ_TYPE_EDGE IRQ_DEFAULT_PRIORITY>,
					<GIC_SPI 401 IRQ_TYPE_EDGE IRQ_DEFAULT_PRIORITY>,
					<GIC_SPI 402 IRQ_TYPE_EDGE IRQ_DEFAULT_PRIORITY>,
					<GIC_SPI 403 IRQ_TYPE_EDGE IRQ_DEFAULT_PRIORITY>;
			interrupt-names = "ccmpa", "ccmpb", "cmpc", "cmpd", "cmpe",
					  "cmpf", "ovf", "udf";
			prescaler = <1>;
			status = "disabled";

			pwm {
				compatible = "renesas,rz-gpt-pwm";
				#pwm-cells = <3>;
				status = "disabled";
			};
		};

		gpt15: gpt15@81000100 {
			compatible = "renesas,rz-gpt";
			reg = <0x81000100 0x100>;
			channel = <15>;
			interrupts = <GIC_SPI 404 IRQ_TYPE_EDGE IRQ_DEFAULT_PRIORITY>,
					<GIC_SPI 405 IRQ_TYPE_EDGE IRQ_DEFAULT_PRIORITY>,
					<GIC_SPI 406 IRQ_TYPE_EDGE IRQ_DEFAULT_PRIORITY>,
					<GIC_SPI 407 IRQ_TYPE_EDGE IRQ_DEFAULT_PRIORITY>,
					<GIC_SPI 408 IRQ_TYPE_EDGE IRQ_DEFAULT_PRIORITY>,
					<GIC_SPI 409 IRQ_TYPE_EDGE IRQ_DEFAULT_PRIORITY>,
					<GIC_SPI 410 IRQ_TYPE_EDGE IRQ_DEFAULT_PRIORITY>,
					<GIC_SPI 411 IRQ_TYPE_EDGE IRQ_DEFAULT_PRIORITY>;
			interrupt-names = "ccmpa", "ccmpb", "cmpc", "cmpd", "cmpe",
					  "cmpf", "ovf", "udf";
			prescaler = <1>;
			status = "disabled";

			pwm {
				compatible = "renesas,rz-gpt-pwm";
				#pwm-cells = <3>;
				status = "disabled";
			};
		};

		gpt16: gpt16@81000200 {
			compatible = "renesas,rz-gpt";
			reg = <0x81000200 0x100>;
			channel = <16>;
			interrupts = <GIC_SPI 412 IRQ_TYPE_EDGE IRQ_DEFAULT_PRIORITY>,
					<GIC_SPI 413 IRQ_TYPE_EDGE IRQ_DEFAULT_PRIORITY>,
					<GIC_SPI 414 IRQ_TYPE_EDGE IRQ_DEFAULT_PRIORITY>,
					<GIC_SPI 415 IRQ_TYPE_EDGE IRQ_DEFAULT_PRIORITY>,
					<GIC_SPI 416 IRQ_TYPE_EDGE IRQ_DEFAULT_PRIORITY>,
					<GIC_SPI 417 IRQ_TYPE_EDGE IRQ_DEFAULT_PRIORITY>,
					<GIC_SPI 418 IRQ_TYPE_EDGE IRQ_DEFAULT_PRIORITY>,
					<GIC_SPI 419 IRQ_TYPE_EDGE IRQ_DEFAULT_PRIORITY>;
			interrupt-names = "ccmpa", "ccmpb", "cmpc", "cmpd", "cmpe",
					  "cmpf", "ovf", "udf";
			prescaler = <1>;
			status = "disabled";

			pwm {
				compatible = "renesas,rz-gpt-pwm";
				#pwm-cells = <3>;
				status = "disabled";
			};
		};

		gpt17: gpt17@81000300 {
			compatible = "renesas,rz-gpt";
			reg = <0x81000300 0x100>;
			channel = <17>;
			interrupts = <GIC_SPI 420 IRQ_TYPE_EDGE IRQ_DEFAULT_PRIORITY>,
					<GIC_SPI 421 IRQ_TYPE_EDGE IRQ_DEFAULT_PRIORITY>,
					<GIC_SPI 422 IRQ_TYPE_EDGE IRQ_DEFAULT_PRIORITY>,
					<GIC_SPI 423 IRQ_TYPE_EDGE IRQ_DEFAULT_PRIORITY>,
					<GIC_SPI 424 IRQ_TYPE_EDGE IRQ_DEFAULT_PRIORITY>,
					<GIC_SPI 425 IRQ_TYPE_EDGE IRQ_DEFAULT_PRIORITY>,
					<GIC_SPI 426 IRQ_TYPE_EDGE IRQ_DEFAULT_PRIORITY>,
					<GIC_SPI 427 IRQ_TYPE_EDGE IRQ_DEFAULT_PRIORITY>;
			interrupt-names = "ccmpa", "ccmpb", "cmpc", "cmpd", "cmpe",
					  "cmpf", "ovf", "udf";
			prescaler = <1>;
			status = "disabled";

			pwm {
				compatible = "renesas,rz-gpt-pwm";
				#pwm-cells = <3>;
				status = "disabled";
			};
		};
	};
};
